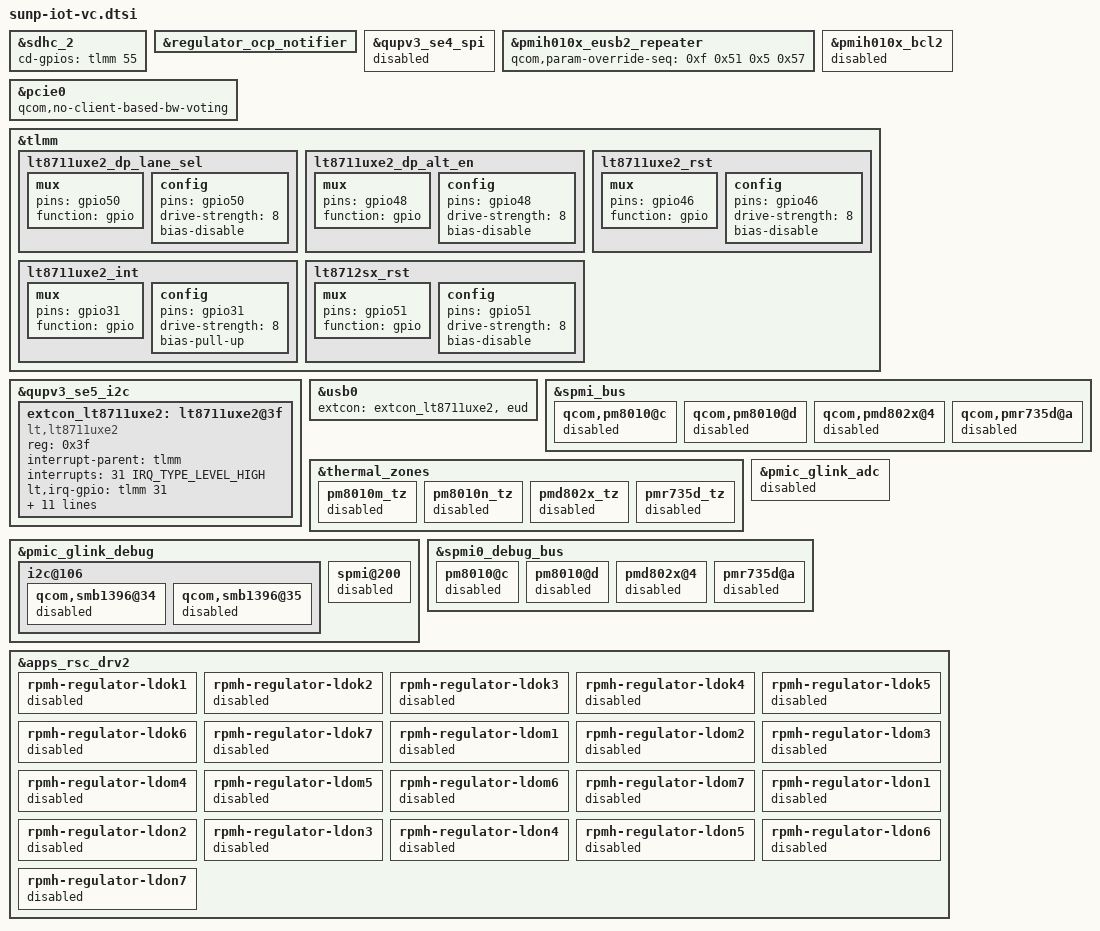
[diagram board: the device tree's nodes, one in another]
// SPDX-License-Identifier: BSD-3-Clause
/*
 * Copyright (c) Qualcomm Technologies, Inc. and/or its subsidiaries.
 */

#include "sun-qrd-sku1-v8.dtsi"

&sdhc_2 {
	cd-gpios = <&tlmm 55 GPIO_ACTIVE_HIGH>;
};

&regulator_ocp_notifier {
	/delete-property/ periph-ac1-supply;
	/delete-property/ periph-ac2-supply;
	/delete-property/ periph-ac3-supply;
	/delete-property/ periph-ac4-supply;
	/delete-property/ periph-ac5-supply;
	/delete-property/ periph-ac6-supply;
	/delete-property/ periph-ac7-supply;
	/delete-property/ periph-c40-supply;
	/delete-property/ periph-c41-supply;
	/delete-property/ periph-c42-supply;
	/delete-property/ periph-c43-supply;
	/delete-property/ periph-c44-supply;
	/delete-property/ periph-c45-supply;
	/delete-property/ periph-c46-supply;
	/delete-property/ periph-d40-supply;
	/delete-property/ periph-d41-supply;
	/delete-property/ periph-d42-supply;
	/delete-property/ periph-d43-supply;
	/delete-property/ periph-d44-supply;
	/delete-property/ periph-d45-supply;
	/delete-property/ periph-d46-supply;
};

&qupv3_se4_spi {
	status = "disabled";
};

&pmih010x_eusb2_repeater {
	qcom,param-override-seq =
		/* <value reg_offset> */
		/* Adjust HS trasmit amplitude */
		<0xf 0x51
		/* Tx pre-emphasis tuning */
		0x5 0x57>;
};

&pmih010x_bcl2 {
	status = "disabled";
};
&pcie0 {
	qcom,no-client-based-bw-voting;
};

&tlmm {
	 lt8711uxe2_dp_lane_sel: lt8711uxe2_dp_lane_sel {
		 mux {
			 pins = "gpio50";
			 function = "gpio";
		 };

		 config {
			 pins = "gpio50";
			 drive-strength = <8>;
			 bias-disable;
		 };
	 };

	 lt8711uxe2_dp_alt_en: lt8711uxe2_dp_alt_en {
		 mux {
			 pins = "gpio48";
			 function = "gpio";
		 };

		 config {
			 pins = "gpio48";
			 drive-strength = <8>;
			 bias-disable;
		 };
	 };


	 lt8711uxe2_rst: lt8711uxe2_rst {
		 mux {
			 pins = "gpio46";
			 function = "gpio";
		 };

		 config {
			 pins = "gpio46";
			 drive-strength = <8>;
			 bias-disable;
		 };
	 };

	 lt8711uxe2_int: lt8711uxe2_int {
		 mux {
			 pins = "gpio31";
			 function = "gpio";
		 };

		 config {
			 pins = "gpio31";
			 drive-strength = <8>;
			 bias-pull-up;
		 };
	 };

	lt8712sx_rst: lt8712sx_rst {
		mux {
			pins = "gpio51";
			function = "gpio";
		};

		config {
			pins = "gpio51";
			drive-strength = <8>;
			bias-disable;
		};
	};
};


&qupv3_se5_i2c {
	status = "ok";
	extcon_lt8711uxe2: lt8711uxe2@3f {
		compatible = "lt,lt8711uxe2";
		reg = <0x3f>;
		interrupt-parent = <&tlmm>;
		interrupts = <31 IRQ_TYPE_LEVEL_HIGH>;
		lt,irq-gpio = <&tlmm 31 0>;
		lt,dp-lane-sel = <&tlmm 50 0>;
		lt,dp-alt-en = <&tlmm 48 0>;
		lt,reset-gpio = <&tlmm 46 0>;
		lt,cc-gpio = <&tlmm 68 0>;
		control-ramdump;
		with-hdmi-switch;
		usb-ss-support;
		pinctrl-names = "default";
		pinctrl-0 = <&lt8711uxe2_int &lt8711uxe2_dp_alt_en
			&lt8711uxe2_dp_lane_sel &lt8711uxe2_rst>;
		img-fw-rev = <0x000004>;
		status = "okay";
	};
};

&usb0 {
	extcon = <&extcon_lt8711uxe2>, <&eud>;
};

&spmi_bus {
	qcom,pm8010@c {
		status = "disabled";
	};

	qcom,pm8010@d {
		status = "disabled";
	};

	qcom,pmd802x@4 {
		status = "disabled";
	};

	qcom,pmr735d@a {
		status = "disabled";
	};
};

&thermal_zones {
	pm8010m_tz {
		status = "disabled";
	};

	pm8010n_tz {
		status = "disabled";
	};

	pmd802x_tz {
		status = "disabled";
	};

	pmr735d_tz {
		status = "disabled";
	};
};

&pmic_glink_adc {
	status = "disabled";
};

&pmic_glink_debug {
	i2c@106 {
		qcom,smb1396@34 {
			status = "disabled";
		};

		qcom,smb1396@35 {
			status = "disabled";
		};
	};

	spmi@200 {
		status = "disabled";
	};
};

&spmi0_debug_bus {
	pm8010@c {
		status = "disabled";
	};

	pm8010@d {
		status = "disabled";
	};

	pmd802x@4 {
		status = "disabled";
	};

	pmr735d@a {
		status = "disabled";
	};
};

&apps_rsc_drv2 {
	rpmh-regulator-ldok1 {
		status = "disabled";
	};

	rpmh-regulator-ldok2 {
		status = "disabled";
	};

	rpmh-regulator-ldok3 {
		status = "disabled";
	};

	rpmh-regulator-ldok4 {
		status = "disabled";
	};

	rpmh-regulator-ldok5 {
		status = "disabled";
	};

	rpmh-regulator-ldok6 {
		status = "disabled";
	};

	rpmh-regulator-ldok7 {
		status = "disabled";
	};

	rpmh-regulator-ldom1 {
		status = "disabled";
	};

	rpmh-regulator-ldom2 {
		status = "disabled";
	};

	rpmh-regulator-ldom3 {
		status = "disabled";
	};

	rpmh-regulator-ldom4 {
		status = "disabled";
	};

	rpmh-regulator-ldom5 {
		status = "disabled";
	};

	rpmh-regulator-ldom6 {
		status = "disabled";
	};

	rpmh-regulator-ldom7 {
		status = "disabled";
	};

	rpmh-regulator-ldon1 {
		status = "disabled";
	};

	rpmh-regulator-ldon2 {
		status = "disabled";
	};

	rpmh-regulator-ldon3 {
		status = "disabled";
	};

	rpmh-regulator-ldon4 {
		status = "disabled";
	};

	rpmh-regulator-ldon5 {
		status = "disabled";
	};

	rpmh-regulator-ldon6 {
		status = "disabled";
	};

	rpmh-regulator-ldon7 {
		status = "disabled";
	};
};

